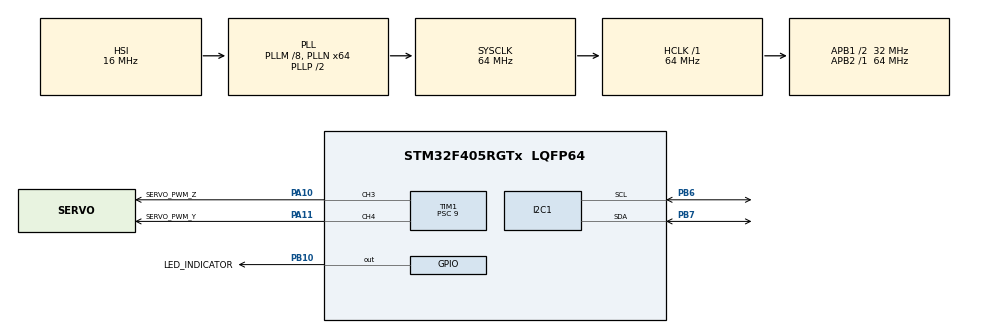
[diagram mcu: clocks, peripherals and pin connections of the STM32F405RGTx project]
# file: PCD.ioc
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Mcu.Family=STM32F4
Mcu.Name=STM32F405RGTx
Mcu.Package=LQFP64
NVIC.PriorityGroup=NVIC_PRIORITYGROUP_4
PA10.GPIO_Label=SERVO_PWM_Z
PA10.Signal=S_TIM1_CH3
PA11.GPIO_Label=SERVO_PWM_Y
PA11.Signal=S_TIM1_CH4
PA13.Mode=Serial_Wire
PA13.Signal=SYS_JTMS-SWDIO
PA14.Mode=Serial_Wire
PA14.Signal=SYS_JTCK-SWCLK
PB10.GPIO_Label=LED_INDICATOR
PB10.Signal=GPIO_Output
PB6.GPIO_Pu=GPIO_PULLUP
PB6.GPIO_Speed=GPIO_SPEED_FREQ_HIGH
PB6.Mode=I2C
PB6.Signal=I2C1_SCL
PB7.GPIO_Pu=GPIO_PULLUP
PB7.GPIO_Speed=GPIO_SPEED_FREQ_HIGH
PB7.Mode=I2C
PB7.Signal=I2C1_SDA
PH0-OSC_IN.Mode=HSE-External-Oscillator
PH0-OSC_IN.Signal=RCC_OSC_IN
PH1-OSC_OUT.Mode=HSE-External-Oscillator
PH1-OSC_OUT.Signal=RCC_OSC_OUT
ProjectManager.HeapSize=0x200
ProjectManager.StackSize=0x400
ProjectManager.TargetToolchain=Makefile
RCC.48MHZClocksFreq_Value=32000000
RCC.AHBFreq_Value=64000000
RCC.APB1CLKDivider=RCC_HCLK_DIV2
RCC.APB1Freq_Value=32000000
RCC.APB1TimFreq_Value=64000000
RCC.APB2Freq_Value=64000000
RCC.APB2TimFreq_Value=64000000
RCC.CortexFreq_Value=64000000
RCC.HCLKFreq_Value=64000000
RCC.HSE_VALUE=25000000
RCC.HSI_VALUE=16000000
RCC.LSE_VALUE=32768
RCC.PLLM=8
RCC.PLLN=64
RCC.SYSCLKFreq_VALUE=64000000
RCC.SYSCLKSource=RCC_SYSCLKSOURCE_PLLCLK
RCC.VCOOutputFreq_Value=128000000
SH.S_TIM1_CH3.0=TIM1_CH3,PWM Generation3 CH3
SH.S_TIM1_CH4.0=TIM1_CH4,PWM Generation4 CH4
TIM1.AutoReloadPreload=TIM_AUTORELOAD_PRELOAD_ENABLE
TIM1.Channel-PWM\ Generation3\ CH3=TIM_CHANNEL_3
TIM1.Channel-PWM\ Generation4\ CH4=TIM_CHANNEL_4
TIM1.Period=64000
TIM1.Prescaler=9
TIM1.Pulse-PWM\ Generation3\ CH3=0
TIM1.Pulse-PWM\ Generation4\ CH4=0
board=custom

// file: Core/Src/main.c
/* USER CODE BEGIN Header */
/**
  ******************************************************************************
  * @file           : main.c
  * @brief          : Main program body
  ******************************************************************************
  * @attention
  *
  * Copyright (c) 2022 STMicroelectronics.
  * All rights reserved.
  *
  * This software is licensed under terms that can be found in the LICENSE file
  * in the root directory of this software component.
  * If no LICENSE file comes with this software, it is provided AS-IS.
  *
  ******************************************************************************
  */
/* USER CODE END Header */
#include "main.h"
#include "i2c.h"
#include "tim.h"
#include "gpio.h"

/* USER CODE BEGIN Includes */
#include "pwm.h"
#include "led_indicator.h"
#include "MCP9808.h"

/* USER CODE END Includes */

/* USER CODE BEGIN PD */
#define SERVO_Y_PWM_CHANNEL TIM_CHANNEL_4
#define SERVO_Z_PWM_CHANNEL TIM_CHANNEL_3
/* USER CODE END PD */

void SystemClock_Config(void);

int main(void)
{

  /* MCU Configuration--------------------------------------------------------*/

  /* Reset of all peripherals, Initializes the Flash interface and the Systick. */
  HAL_Init();

  /* Configure the system clock */
  SystemClock_Config();

  /* Initialize all configured peripherals */
  MX_GPIO_Init();
  MX_TIM1_Init();
  MX_I2C1_Init();
  /* USER CODE BEGIN 2 */
  PWM_Init(&htim1, SERVO_Y_PWM_CHANNEL);
  PWM_Init(&htim1, SERVO_Z_PWM_CHANNEL);

  /* USER CODE END 2 */

  /* Infinite loop */
  while (1)
  {

  }
}

void SystemClock_Config(void)
{
  RCC_OscInitTypeDef RCC_OscInitStruct = {0};
  RCC_ClkInitTypeDef RCC_ClkInitStruct = {0};

  /** Configure the main internal regulator output voltage
  */
  __HAL_RCC_PWR_CLK_ENABLE();
  __HAL_PWR_VOLTAGESCALING_CONFIG(PWR_REGULATOR_VOLTAGE_SCALE1);

  /** Initializes the RCC Oscillators according to the specified parameters
  * in the RCC_OscInitTypeDef structure.
  */
  RCC_OscInitStruct.OscillatorType = RCC_OSCILLATORTYPE_HSI;
  RCC_OscInitStruct.HSIState = RCC_HSI_ON;
  RCC_OscInitStruct.HSICalibrationValue = RCC_HSICALIBRATION_DEFAULT;
  RCC_OscInitStruct.PLL.PLLState = RCC_PLL_ON;
  RCC_OscInitStruct.PLL.PLLSource = RCC_PLLSOURCE_HSI;
  RCC_OscInitStruct.PLL.PLLM = 8;
  RCC_OscInitStruct.PLL.PLLN = 64;
  RCC_OscInitStruct.PLL.PLLP = RCC_PLLP_DIV2;
  RCC_OscInitStruct.PLL.PLLQ = 4;
  if (HAL_RCC_OscConfig(&RCC_OscInitStruct) != HAL_OK)
  {
    Error_Handler();
  }

  /** Initializes the CPU, AHB and APB buses clocks
  */
  RCC_ClkInitStruct.ClockType = RCC_CLOCKTYPE_HCLK|RCC_CLOCKTYPE_SYSCLK
                              |RCC_CLOCKTYPE_PCLK1|RCC_CLOCKTYPE_PCLK2;
  RCC_ClkInitStruct.SYSCLKSource = RCC_SYSCLKSOURCE_PLLCLK;
  RCC_ClkInitStruct.AHBCLKDivider = RCC_SYSCLK_DIV1;
  RCC_ClkInitStruct.APB1CLKDivider = RCC_HCLK_DIV2;
  RCC_ClkInitStruct.APB2CLKDivider = RCC_HCLK_DIV1;

  if (HAL_RCC_ClockConfig(&RCC_ClkInitStruct, FLASH_LATENCY_2) != HAL_OK)
  {
    Error_Handler();
  }
}

void Error_Handler(void)
{
  __disable_irq();
  while (1)
  {
  }
}
